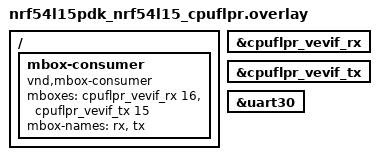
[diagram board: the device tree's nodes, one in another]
/*
 * Copyright 2024 Nordic Semiconductor ASA
 * SPDX-License-Identifier: Apache-2.0
 */

/ {
	mbox-consumer {
		compatible = "vnd,mbox-consumer";
		mboxes = <&cpuflpr_vevif_rx 16>, <&cpuflpr_vevif_tx 15>;
		mbox-names = "rx", "tx";
	};
};

&cpuflpr_vevif_rx {
	status = "okay";
};

&cpuflpr_vevif_tx {
	status = "okay";
};

&uart30 {
	/delete-property/ hw-flow-control;
};
